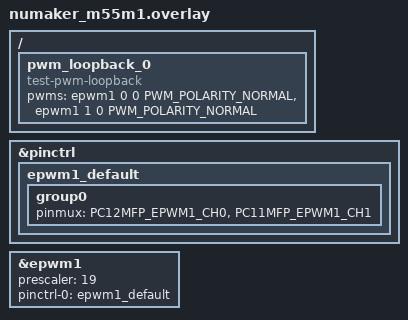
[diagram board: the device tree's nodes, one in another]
/* SPDX-License-Identifier: Apache-2.0 */

#include <zephyr/dt-bindings/pwm/pwm.h>

&pinctrl {
	epwm1_default: epwm1_default {
		group0 {
			/* EVB's D5, D4 --> PC12, PC11 */
			pinmux = <PC12MFP_EPWM1_CH0>,
				 <PC11MFP_EPWM1_CH1>;
		};
	};
};

/ {
	pwm_loopback_0 {
		compatible = "test-pwm-loopback";
		pwms = <&epwm1 0 0 PWM_POLARITY_NORMAL>,
		       <&epwm1 1 0 PWM_POLARITY_NORMAL>;
	};
};

&epwm1 {
	status = "okay";
	prescaler = <19>;
	pinctrl-0 = <&epwm1_default>;
	pinctrl-names = "default";
};
